AUTOSAR XML (schema 314)
package /ComponentType
  internal behavior Sa_CDDInterface_InternalBehavior: component=Sa_CDDInterface
    5 x timing event:
      CDDInterface_Init1_InitEvent: start-on-event=CDDInterface_Init1, period=0
      CDDInterface_Init2_InitEvent: start-on-event=CDDInterface_Init2, period=0
      TMT_CDDInterface_Per1: start-on-event=CDDInterface_Per1, period=0.002
      TMT_CDDInterface_Per2: start-on-event=CDDInterface_Per2, period=0.002
      TMT_CDDInterface_Per4: start-on-event=CDDInterface_Per4, period=0.01
    port-api-options:
      enable-take-address=false, indirect-api=false, port=ADCMtrCurr1
      enable-take-address=false, indirect-api=false, port=ADCMtrCurr2
      enable-take-address=false, indirect-api=false, port=CDDPorts
      enable-take-address=false, indirect-api=false, port=CommOffset
      enable-take-address=false, indirect-api=false, port=CorrectedElecMtrPos
      enable-take-address=false, indirect-api=false, port=CorrMtrCurrPosition
      enable-take-address=false, indirect-api=false, port=CorrMtrPosElec
      enable-take-address=false, indirect-api=false, port=CumMechMtrPos
      enable-take-address=false, indirect-api=false, port=DampingSrlComSvcDft
      enable-take-address=false, indirect-api=false, port=DftAsstTbl
      enable-take-address=false, indirect-api=false, port=Die1RxError
      enable-take-address=false, indirect-api=false, port=Die1RxMtrPos
      enable-take-address=false, indirect-api=false, port=Die1RxRevCtr
      enable-take-address=false, indirect-api=false, port=Die1UnderVoltgFltAccum
      enable-take-address=false, indirect-api=false, port=Die2RxError
      enable-take-address=false, indirect-api=false, port=Die2RxMtrPos
      enable-take-address=false, indirect-api=false, port=Die2RxRevCtr
      enable-take-address=false, indirect-api=false, port=DrivingDynSrlComSvcDft
      enable-take-address=false, indirect-api=false, port=DwnldAsstGain
      enable-take-address=false, indirect-api=false, port=EnergyModeState
      enable-take-address=false, indirect-api=false, port=EngONSrlComSvcDft
      enable-take-address=false, indirect-api=false, port=EOTImpactSrlComSvcDft
      enable-take-address=false, indirect-api=false, port=EOTThermalSrlComSvcDft
      enable-take-address=false, indirect-api=false, port=ExpectedOnTimeA
      enable-take-address=false, indirect-api=false, port=ExpectedOnTimeB
      enable-take-address=false, indirect-api=false, port=ExpectedOnTimeC
      enable-take-address=false, indirect-api=false, port=FreqDepDmpSrlComSvcDft
      enable-take-address=false, indirect-api=false, port=FricLrnSrlComSvcDft
      enable-take-address=false, indirect-api=false, port=HysAddSrlComSvcDft
      enable-take-address=false, indirect-api=false, port=HystCompSrlComSvcDft
      enable-take-address=false, indirect-api=false, port=IgnCnt
      enable-take-address=false, indirect-api=false, port=KinIntDiagSrlComSvcDft
      enable-take-address=false, indirect-api=false, port=LimitSrlComSvcDft
      enable-take-address=false, indirect-api=false, port=LRPRPhaseadvanceCaptured
      enable-take-address=false, indirect-api=false, port=MeasuredOnTimeA
      enable-take-address=false, indirect-api=false, port=MeasuredOnTimeB
      enable-take-address=false, indirect-api=false, port=MeasuredOnTimeC
      enable-take-address=false, indirect-api=false, port=MEC
      enable-take-address=false, indirect-api=false, port=MechMtrPos1
      enable-take-address=false, indirect-api=false, port=MechMtrPos1TimeStamp
      enable-take-address=false, indirect-api=false, port=MechMtrPos2TimeStamp
      enable-take-address=false, indirect-api=false, port=MfgDiagInhibit
      enable-take-address=false, indirect-api=false, port=ModIdxFinal
      enable-take-address=false, indirect-api=false, port=ModIdxSrlComSvcDft
      enable-take-address=false, indirect-api=false, port=MRFMtrVel
      enable-take-address=false, indirect-api=false, port=MtrCurr1TempOffset
      enable-take-address=false, indirect-api=false, port=MtrCurr2TempOffset
      enable-take-address=false, indirect-api=false, port=MtrCurrDax
      enable-take-address=false, indirect-api=false, port=MtrCurrK1
      enable-take-address=false, indirect-api=false, port=MtrCurrK2
      enable-take-address=false, indirect-api=false, port=MtrCurrQax
      enable-take-address=false, indirect-api=false, port=MtrCurrQaxFinalRef
      enable-take-address=false, indirect-api=false, port=MtrElecMechPolarity
      enable-take-address=false, indirect-api=false, port=MtrParmNrmLrnSrlComSvcDft
      enable-take-address=false, indirect-api=false, port=MtrPosPolarity
      enable-take-address=false, indirect-api=false, port=MtrTrqCmdSign
      enable-take-address=false, indirect-api=false, port=MtrVelNrmLrnSrlComSvcDft
      enable-take-address=false, indirect-api=false, port=MtrVoltDax
      enable-take-address=false, indirect-api=false, port=MtrVoltQax
      enable-take-address=false, indirect-api=false, port=MultIgnSrlComSvcDft
      enable-take-address=false, indirect-api=false, port=ParkAstSrlComSvcDft
      enable-take-address=false, indirect-api=false, port=PullCompSrlComSvcDft
      enable-take-address=false, indirect-api=false, port=ReturnSrlComSvcDft
      enable-take-address=false, indirect-api=false, port=RxMsgsSrlComSvcDft
      enable-take-address=false, indirect-api=false, port=RxMtrPosParityAccum
      enable-take-address=false, indirect-api=false, port=SrlComSvcDft
      enable-take-address=false, indirect-api=false, port=SysCCorrMtrPosElec
      enable-take-address=false, indirect-api=false, port=SysCVSwitchADC
      enable-take-address=false, indirect-api=false, port=SystemState
      enable-take-address=false, indirect-api=false, port=ThermalDCSrlComSvcDft
      enable-take-address=false, indirect-api=false, port=TrqRmpSrlComSvcDft
      enable-take-address=false, indirect-api=false, port=UncorrMechMtrPos1
      enable-take-address=false, indirect-api=false, port=Vecu
      enable-take-address=false, indirect-api=false, port=WhlImbRejSrlComSvcDft
    5 x runnable:
      CDDInterface_Init1
        data read access READ_MtrElecMechPolarity_Cnt_s08: data-element=MtrElecMechPolarity.Cnt_s08
        data read access READ_MtrPosPolarity_Cnt_s08: data-element=MtrPosPolarity.Cnt_s08
        data write access WRITE_IgnCnt_Cnt_u16: data-element=IgnCnt.Cnt_u16
        data write access WRITE_MEC_Cnt_enum: data-element=MEC.Cnt_enum
        sync call SC_CDDPorts_ApplyMtrElecMechPol: operation=CDDPorts.ApplyMtrElecMechPol, timeout=0
      CDDInterface_Init2
      CDDInterface_Per1
        35 x data write access:
          WRITE_ADCMtrCurr1_Volts_f32: data-element=ADCMtrCurr1.Volts_f32
          WRITE_ADCMtrCurr2_Volts_f32: data-element=ADCMtrCurr2.Volts_f32
          WRITE_CorrectedElecMtrPos_Rev_u0p16: data-element=CorrectedElecMtrPos.Rev_u0p16
          WRITE_CorrMtrCurrPosition_Rev_f32: data-element=CorrMtrCurrPosition.Rev_f32
          WRITE_CorrMtrPosElec_Rev_f32: data-element=CorrMtrPosElec.Rev_f32
          WRITE_CumMechMtrPos_Rev_f32: data-element=CumMechMtrPos.Rev_f32
          WRITE_Die1RxError_Cnt_u16: data-element=Die1RxError.Cnt_u16
          WRITE_Die1RxMtrPos_Cnt_u16: data-element=Die1RxMtrPos.Cnt_u16
          WRITE_Die1RxRevCtr_Cnt_u16: data-element=Die1RxRevCtr.Cnt_u16
          WRITE_Die1UnderVoltgFltAccum_Cnt_u16: data-element=Die1UnderVoltgFltAccum.Cnt_u16
          WRITE_Die2RxError_Cnt_u16: data-element=Die2RxError.Cnt_u16
          WRITE_Die2RxMtrPos_Cnt_u16: data-element=Die2RxMtrPos.Cnt_u16
          WRITE_Die2RxRevCtr_Cnt_u16: data-element=Die2RxRevCtr.Cnt_u16
          WRITE_ExpectedOnTimeA_Cnt_u32: data-element=ExpectedOnTimeA.Cnt_u32
          WRITE_ExpectedOnTimeB_Cnt_u32: data-element=ExpectedOnTimeB.Cnt_u32
          WRITE_ExpectedOnTimeC_Cnt_u32: data-element=ExpectedOnTimeC.Cnt_u32
          WRITE_LRPRPhaseadvanceCaptured_Cnt_s16: data-element=LRPRPhaseadvanceCaptured.Cnt_s16
          WRITE_MeasuredOnTimeA_Cnt_u32: data-element=MeasuredOnTimeA.Cnt_u32
          WRITE_MeasuredOnTimeB_Cnt_u32: data-element=MeasuredOnTimeB.Cnt_u32
          WRITE_MeasuredOnTimeC_Cnt_u32: data-element=MeasuredOnTimeC.Cnt_u32
          WRITE_MechMtrPos1_Rev_f32: data-element=MechMtrPos1.Rev_f32
          WRITE_MechMtrPos1TimeStamp_USec_u32: data-element=MechMtrPos1TimeStamp.USec_u32
          WRITE_MechMtrPos2TimeStamp_USec_u32: data-element=MechMtrPos2TimeStamp.USec_u32
          WRITE_ModIdxFinal_Uls_f32: data-element=ModIdxFinal.Uls_f32
          WRITE_MtrCurrDax_Amp_f32: data-element=MtrCurrDax.Amp_f32
          WRITE_MtrCurrK1_Amp_f32: data-element=MtrCurrK1.Amp_f32
          WRITE_MtrCurrK2_Amp_f32: data-element=MtrCurrK2.Amp_f32
          WRITE_MtrCurrQax_Amp_f32: data-element=MtrCurrQax.Amp_f32
          WRITE_MtrCurrQaxFinalRef_Amp_f32: data-element=MtrCurrQaxFinalRef.Amp_f32
          WRITE_MtrVoltDax_Volt_f32: data-element=MtrVoltDax.Volt_f32
          WRITE_MtrVoltQax_Volt_f32: data-element=MtrVoltQax.Volt_f32
          WRITE_RxMtrPosParityAccum_Cnt_u16: data-element=RxMtrPosParityAccum.Cnt_u16
          WRITE_SysCCorrMtrPosElec_Rev_f32: data-element=SysCCorrMtrPosElec.Rev_f32
          WRITE_SysCVSwitchADC_Cnt_u16: data-element=SysCVSwitchADC.Cnt_u16
          WRITE_UncorrMechMtrPos1_Rev_u0p16: data-element=UncorrMechMtrPos1.Rev_u0p16
        sync call SC_CDDPorts_ClearPhsReasSum: operation=CDDPorts.ClearPhsReasSum, timeout=0
      CDDInterface_Per2
        7 x data read access:
          READ_CommOffset_Cnt_u16: data-element=CommOffset.Cnt_u16
          READ_MRFMtrVel_MtrRadpS_f32: data-element=MRFMtrVel.MtrRadpS_f32
          READ_MtrCurr1TempOffset_Volt_f32: data-element=MtrCurr1TempOffset.Volt_f32
          READ_MtrCurr2TempOffset_Volt_f32: data-element=MtrCurr2TempOffset.Volt_f32
          READ_MtrPosPolarity_Cnt_s08: data-element=MtrPosPolarity.Cnt_s08
          READ_MtrTrqCmdSign_Cnt_s16: data-element=MtrTrqCmdSign.Cnt_s16
          READ_Vecu_Volt_f32: data-element=Vecu.Volt_f32
      CDDInterface_Per4
        data read access READ_MtrElecMechPolarity_Cnt_s08: data-element=MtrElecMechPolarity.Cnt_s08
        27 x data write access:
          WRITE_DampingSrlComSvcDft_Cnt_lgc: data-element=DampingSrlComSvcDft.Cnt_lgc
          WRITE_DftAsstTbl_Cnt_lgc: data-element=DftAsstTbl.Cnt_lgc
          WRITE_DrivingDynSrlComSvcDft_Cnt_lgc: data-element=DrivingDynSrlComSvcDft.Cnt_lgc
          WRITE_DwnldAsstGain_Uls_f32: data-element=DwnldAsstGain.Uls_f32
          WRITE_EnergyModeState_Cnt_enum: data-element=EnergyModeState.Cnt_enum
          WRITE_EngONSrlComSvcDft_Cnt_lgc: data-element=EngONSrlComSvcDft.Cnt_lgc
          WRITE_EOTImpactSrlComSvcDft_Cnt_lgc: data-element=EOTImpactSrlComSvcDft.Cnt_lgc
          WRITE_EOTThermalSrlComSvcDft_Cnt_lgc: data-element=EOTThermalSrlComSvcDft.Cnt_lgc
          WRITE_FreqDepDmpSrlComSvcDft_Cnt_lgc: data-element=FreqDepDmpSrlComSvcDft.Cnt_lgc
          WRITE_FricLrnSrlComSvcDft_Cnt_lgc: data-element=FricLrnSrlComSvcDft.Cnt_lgc
          WRITE_HysAddSrlComSvcDft_Cnt_lgc: data-element=HysAddSrlComSvcDft.Cnt_lgc
          WRITE_HystCompSrlComSvcDft_Cnt_lgc: data-element=HystCompSrlComSvcDft.Cnt_lgc
          WRITE_KinIntDiagSrlComSvcDft_Cnt_lgc: data-element=KinIntDiagSrlComSvcDft.Cnt_lgc
          WRITE_LimitSrlComSvcDft_Cnt_lgc: data-element=LimitSrlComSvcDft.Cnt_lgc
          WRITE_MfgDiagInhibit_Cnt_lgc: data-element=MfgDiagInhibit.Cnt_lgc
          WRITE_ModIdxSrlComSvcDft_Cnt_lgc: data-element=ModIdxSrlComSvcDft.Cnt_lgc
          WRITE_MtrParmNrmLrnSrlComSvcDft_Cnt_lgc: data-element=MtrParmNrmLrnSrlComSvcDft.Cnt_lgc
          WRITE_MtrVelNrmLrnSrlComSvcDft_Cnt_lgc: data-element=MtrVelNrmLrnSrlComSvcDft.Cnt_lgc
          WRITE_MultIgnSrlComSvcDft_Cnt_lgc: data-element=MultIgnSrlComSvcDft.Cnt_lgc
          WRITE_ParkAstSrlComSvcDft_Cnt_lgc: data-element=ParkAstSrlComSvcDft.Cnt_lgc
          WRITE_PullCompSrlComSvcDft_Cnt_lgc: data-element=PullCompSrlComSvcDft.Cnt_lgc
          WRITE_ReturnSrlComSvcDft_Cnt_lgc: data-element=ReturnSrlComSvcDft.Cnt_lgc
          WRITE_RxMsgsSrlComSvcDft_Cnt_lgc: data-element=RxMsgsSrlComSvcDft.Cnt_lgc
          WRITE_SrlComSvcDft_Cnt_b32: data-element=SrlComSvcDft.Cnt_b32
          WRITE_ThermalDCSrlComSvcDft_Cnt_lgc: data-element=ThermalDCSrlComSvcDft.Cnt_lgc
          WRITE_TrqRmpSrlComSvcDft_Cnt_lgc: data-element=TrqRmpSrlComSvcDft.Cnt_lgc
          WRITE_WhlImbRejSrlComSvcDft_Cnt_lgc: data-element=WhlImbRejSrlComSvcDft.Cnt_lgc
        sync call SC_CDDPorts_ApplyMtrElecMechPol: operation=CDDPorts.ApplyMtrElecMechPol, timeout=0
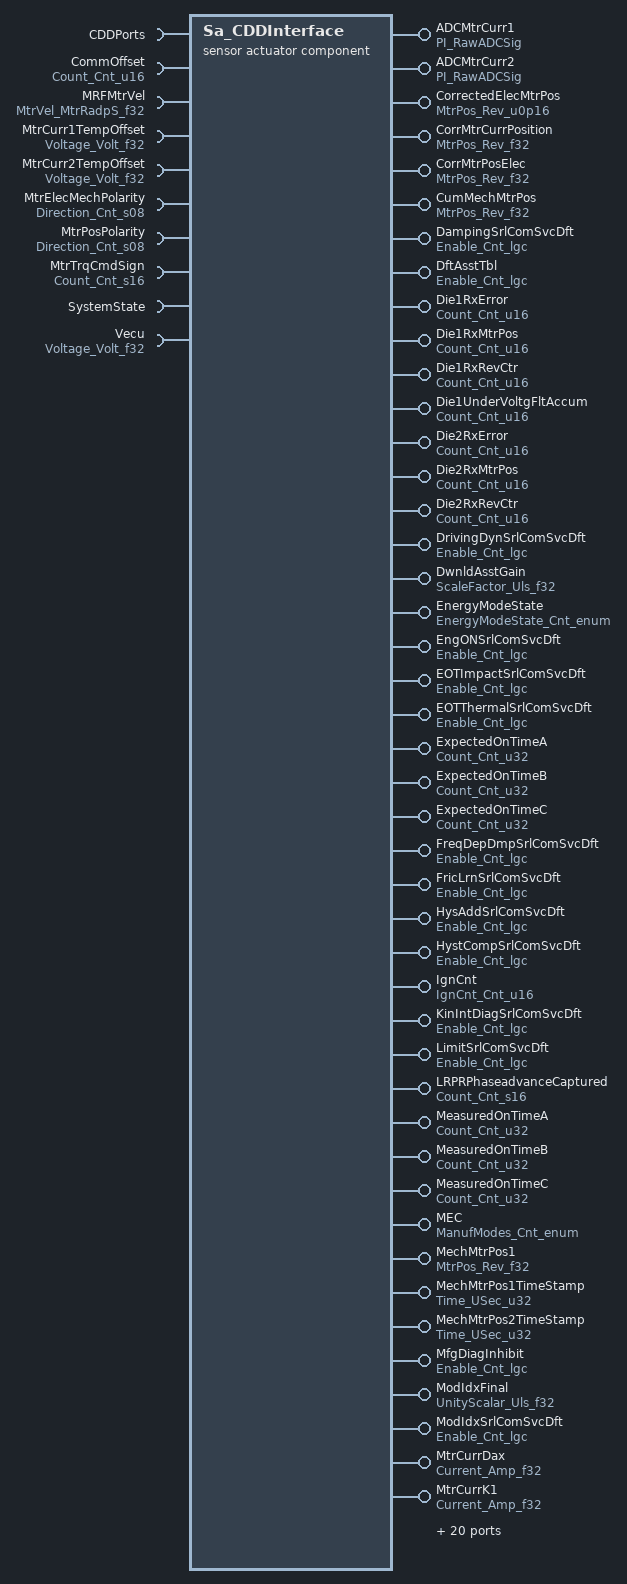
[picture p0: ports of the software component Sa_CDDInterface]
  sensor actuator software component type Sa_CDDInterface
    64 x provide port:
      ADCMtrCurr1: unqueued-sender-com-spec{data-element=Volts_f32, can-invalidate=false, init-value=D_ZERO_ULS_F32}, provided-interface=PI_RawADCSig
      ADCMtrCurr2: unqueued-sender-com-spec{data-element=Volts_f32, can-invalidate=false, init-value=D_ZERO_ULS_F32}, provided-interface=PI_RawADCSig
      CorrectedElecMtrPos: unqueued-sender-com-spec{data-element=Rev_u0p16, can-invalidate=false, init-value=D_ZERO_CNT_U16}, provided-interface=MtrPos_Rev_u0p16
      CorrMtrCurrPosition: unqueued-sender-com-spec{data-element=Rev_f32, can-invalidate=false, init-value=D_ZERO_ULS_F32}, provided-interface=MtrPos_Rev_f32
      CorrMtrPosElec: unqueued-sender-com-spec{data-element=Rev_f32, can-invalidate=false, init-value=D_ZERO_ULS_F32}, provided-interface=MtrPos_Rev_f32
      CumMechMtrPos: unqueued-sender-com-spec{data-element=Rev_f32, can-invalidate=false, init-value=D_ZERO_ULS_F32}, provided-interface=MtrPos_Rev_f32
      DampingSrlComSvcDft: unqueued-sender-com-spec{data-element=Cnt_lgc, can-invalidate=false, init-value=D_FALSE_CNT_LGC}, provided-interface=Enable_Cnt_lgc
      DftAsstTbl: unqueued-sender-com-spec{data-element=Cnt_lgc, can-invalidate=false, init-value=D_FALSE_CNT_LGC}, provided-interface=Enable_Cnt_lgc
      Die1RxError: unqueued-sender-com-spec{data-element=Cnt_u16, can-invalidate=false, init-value=D_ZERO_CNT_U16}, provided-interface=Count_Cnt_u16
      Die1RxMtrPos: unqueued-sender-com-spec{data-element=Cnt_u16, can-invalidate=false, init-value=D_ZERO_CNT_U16}, provided-interface=Count_Cnt_u16
      Die1RxRevCtr: unqueued-sender-com-spec{data-element=Cnt_u16, can-invalidate=false, init-value=D_ZERO_CNT_U16}, provided-interface=Count_Cnt_u16
      Die1UnderVoltgFltAccum: unqueued-sender-com-spec{data-element=Cnt_u16, can-invalidate=false, init-value=D_ZERO_CNT_U16}, provided-interface=Count_Cnt_u16
      Die2RxError: unqueued-sender-com-spec{data-element=Cnt_u16, can-invalidate=false, init-value=D_ZERO_CNT_U16}, provided-interface=Count_Cnt_u16
      Die2RxMtrPos: unqueued-sender-com-spec{data-element=Cnt_u16, can-invalidate=false, init-value=D_ZERO_CNT_U16}, provided-interface=Count_Cnt_u16
      Die2RxRevCtr: unqueued-sender-com-spec{data-element=Cnt_u16, can-invalidate=false, init-value=D_ZERO_CNT_U16}, provided-interface=Count_Cnt_u16
      DrivingDynSrlComSvcDft: unqueued-sender-com-spec{data-element=Cnt_lgc, can-invalidate=false, init-value=D_FALSE_CNT_LGC}, provided-interface=Enable_Cnt_lgc
      DwnldAsstGain: unqueued-sender-com-spec{data-element=Uls_f32, can-invalidate=false, init-value=D_ZERO_ULS_F32}, provided-interface=ScaleFactor_Uls_f32
      EnergyModeState: unqueued-sender-com-spec{data-element=Cnt_enum, can-invalidate=false, init-value=D_NORMALINIT_CNT_U16}, provided-interface=EnergyModeState_Cnt_enum
      EngONSrlComSvcDft: unqueued-sender-com-spec{data-element=Cnt_lgc, can-invalidate=false, init-value=D_FALSE_CNT_LGC}, provided-interface=Enable_Cnt_lgc
      EOTImpactSrlComSvcDft: unqueued-sender-com-spec{data-element=Cnt_lgc, can-invalidate=false, init-value=D_FALSE_CNT_LGC}, provided-interface=Enable_Cnt_lgc
      EOTThermalSrlComSvcDft: unqueued-sender-com-spec{data-element=Cnt_lgc, can-invalidate=false, init-value=D_FALSE_CNT_LGC}, provided-interface=Enable_Cnt_lgc
      ExpectedOnTimeA: unqueued-sender-com-spec{data-element=Cnt_u32, can-invalidate=false, init-value=D_ZERO_CNT_U32}, provided-interface=Count_Cnt_u32
      ExpectedOnTimeB: unqueued-sender-com-spec{data-element=Cnt_u32, can-invalidate=false, init-value=D_ZERO_CNT_U32}, provided-interface=Count_Cnt_u32
      ExpectedOnTimeC: unqueued-sender-com-spec{data-element=Cnt_u32, can-invalidate=false, init-value=D_ZERO_CNT_U32}, provided-interface=Count_Cnt_u32
      FreqDepDmpSrlComSvcDft: unqueued-sender-com-spec{data-element=Cnt_lgc, can-invalidate=false, init-value=D_FALSE_CNT_LGC}, provided-interface=Enable_Cnt_lgc
      FricLrnSrlComSvcDft: unqueued-sender-com-spec{data-element=Cnt_lgc, can-invalidate=false, init-value=D_FALSE_CNT_LGC}, provided-interface=Enable_Cnt_lgc
      HysAddSrlComSvcDft: unqueued-sender-com-spec{data-element=Cnt_lgc, can-invalidate=false, init-value=D_FALSE_CNT_LGC}, provided-interface=Enable_Cnt_lgc
      HystCompSrlComSvcDft: unqueued-sender-com-spec{data-element=Cnt_lgc, can-invalidate=false, init-value=D_FALSE_CNT_LGC}, provided-interface=Enable_Cnt_lgc
      IgnCnt: unqueued-sender-com-spec{data-element=Cnt_u16, can-invalidate=false, init-value=D_ZERO_CNT_U16}, provided-interface=IgnCnt_Cnt_u16
      KinIntDiagSrlComSvcDft: unqueued-sender-com-spec{data-element=Cnt_lgc, can-invalidate=false, init-value=D_FALSE_CNT_LGC}, provided-interface=Enable_Cnt_lgc
      LimitSrlComSvcDft: unqueued-sender-com-spec{data-element=Cnt_lgc, can-invalidate=false, init-value=D_FALSE_CNT_LGC}, provided-interface=Enable_Cnt_lgc
      LRPRPhaseadvanceCaptured: unqueued-sender-com-spec{data-element=Cnt_s16, can-invalidate=false, init-value=D_ZERO_CNT_S16}, provided-interface=Count_Cnt_s16
      MeasuredOnTimeA: unqueued-sender-com-spec{data-element=Cnt_u32, can-invalidate=false, init-value=D_ZERO_CNT_U32}, provided-interface=Count_Cnt_u32
      MeasuredOnTimeB: unqueued-sender-com-spec{data-element=Cnt_u32, can-invalidate=false, init-value=D_ZERO_CNT_U32}, provided-interface=Count_Cnt_u32
      MeasuredOnTimeC: unqueued-sender-com-spec{data-element=Cnt_u32, can-invalidate=false, init-value=D_ZERO_CNT_U32}, provided-interface=Count_Cnt_u32
      MEC: unqueued-sender-com-spec{data-element=Cnt_enum, can-invalidate=false, init-value=D_MANUFMODEINIT_CNT_ENUM}, provided-interface=ManufModes_Cnt_enum
      MechMtrPos1: unqueued-sender-com-spec{data-element=Rev_f32, can-invalidate=false, init-value=D_ZERO_ULS_F32}, provided-interface=MtrPos_Rev_f32
      MechMtrPos1TimeStamp: unqueued-sender-com-spec{data-element=USec_u32, can-invalidate=false, init-value=D_ZERO_CNT_U32}, provided-interface=Time_USec_u32
      MechMtrPos2TimeStamp: unqueued-sender-com-spec{data-element=USec_u32, can-invalidate=false, init-value=D_ZERO_CNT_U32}, provided-interface=Time_USec_u32
      MfgDiagInhibit: unqueued-sender-com-spec{data-element=Cnt_lgc, can-invalidate=false, init-value=D_FALSE_CNT_LGC}, provided-interface=Enable_Cnt_lgc
      ModIdxFinal: unqueued-sender-com-spec{data-element=Uls_f32, can-invalidate=false, init-value=D_ZERO_ULS_F32}, provided-interface=UnityScalar_Uls_f32
      ModIdxSrlComSvcDft: unqueued-sender-com-spec{data-element=Cnt_lgc, can-invalidate=false, init-value=D_FALSE_CNT_LGC}, provided-interface=Enable_Cnt_lgc
      MtrCurrDax: unqueued-sender-com-spec{data-element=Amp_f32, can-invalidate=false, init-value=D_ZERO_ULS_F32}, provided-interface=Current_Amp_f32
      MtrCurrK1: unqueued-sender-com-spec{data-element=Amp_f32, can-invalidate=false, init-value=D_ZERO_ULS_F32}, provided-interface=Current_Amp_f32
      MtrCurrK2: unqueued-sender-com-spec{data-element=Amp_f32, can-invalidate=false, init-value=D_ZERO_ULS_F32}, provided-interface=Current_Amp_f32
      MtrCurrQax: unqueued-sender-com-spec{data-element=Amp_f32, can-invalidate=false, init-value=D_ZERO_ULS_F32}, provided-interface=Current_Amp_f32
      MtrCurrQaxFinalRef: unqueued-sender-com-spec{data-element=Amp_f32, can-invalidate=false, init-value=D_ZERO_ULS_F32}, provided-interface=Current_Amp_f32
      MtrParmNrmLrnSrlComSvcDft: unqueued-sender-com-spec{data-element=Cnt_lgc, can-invalidate=false, init-value=D_FALSE_CNT_LGC}, provided-interface=Enable_Cnt_lgc
      MtrVelNrmLrnSrlComSvcDft: unqueued-sender-com-spec{data-element=Cnt_lgc, can-invalidate=false, init-value=D_FALSE_CNT_LGC}, provided-interface=Enable_Cnt_lgc
      MtrVoltDax: unqueued-sender-com-spec{data-element=Volt_f32, can-invalidate=false, init-value=D_ZERO_ULS_F32}, provided-interface=Voltage_Volt_f32
      MtrVoltQax: unqueued-sender-com-spec{data-element=Volt_f32, can-invalidate=false, init-value=D_ZERO_ULS_F32}, provided-interface=Voltage_Volt_f32
      MultIgnSrlComSvcDft: unqueued-sender-com-spec{data-element=Cnt_lgc, can-invalidate=false, init-value=D_FALSE_CNT_LGC}, provided-interface=Enable_Cnt_lgc
      ParkAstSrlComSvcDft: unqueued-sender-com-spec{data-element=Cnt_lgc, can-invalidate=false, init-value=D_FALSE_CNT_LGC}, provided-interface=Enable_Cnt_lgc
      PullCompSrlComSvcDft: unqueued-sender-com-spec{data-element=Cnt_lgc, can-invalidate=false, init-value=D_FALSE_CNT_LGC}, provided-interface=Enable_Cnt_lgc
      ReturnSrlComSvcDft: unqueued-sender-com-spec{data-element=Cnt_lgc, can-invalidate=false, init-value=D_FALSE_CNT_LGC}, provided-interface=Enable_Cnt_lgc
      RxMsgsSrlComSvcDft: unqueued-sender-com-spec{data-element=Cnt_lgc, can-invalidate=false, init-value=D_FALSE_CNT_LGC}, provided-interface=Enable_Cnt_lgc
      RxMtrPosParityAccum: unqueued-sender-com-spec{data-element=Cnt_u16, can-invalidate=false, init-value=D_ZERO_CNT_U16}, provided-interface=Count_Cnt_u16
      SrlComSvcDft: unqueued-sender-com-spec{data-element=Cnt_b32, can-invalidate=false, init-value=D_ZERO_CNT_U32}, provided-interface=SrlComSvcDft
      SysCCorrMtrPosElec: unqueued-sender-com-spec{data-element=Rev_f32, can-invalidate=false, init-value=D_ZERO_ULS_F32}, provided-interface=MtrPos_Rev_f32
      SysCVSwitchADC: unqueued-sender-com-spec{data-element=Cnt_u16, can-invalidate=false, init-value=D_ZERO_CNT_U16}, provided-interface=Count_Cnt_u16
      ThermalDCSrlComSvcDft: unqueued-sender-com-spec{data-element=Cnt_lgc, can-invalidate=false, init-value=D_FALSE_CNT_LGC}, provided-interface=Enable_Cnt_lgc
      TrqRmpSrlComSvcDft: unqueued-sender-com-spec{data-element=Cnt_lgc, can-invalidate=false, init-value=D_FALSE_CNT_LGC}, provided-interface=Enable_Cnt_lgc
      UncorrMechMtrPos1: unqueued-sender-com-spec{data-element=Rev_u0p16, can-invalidate=false, init-value=D_ZERO_CNT_U16}, provided-interface=MtrPos_Rev_u0p16
      WhlImbRejSrlComSvcDft: unqueued-sender-com-spec{data-element=Cnt_lgc, can-invalidate=false, init-value=D_FALSE_CNT_LGC}, provided-interface=Enable_Cnt_lgc
    10 x require port:
      CDDPorts: required-com-specs=[ApplyMtrElecMechPol, ClearPhsReasSum], required-interface=CDDPorts
      CommOffset: unqueued-receiver-com-spec{data-element=Cnt_u16, init-value=D_ZERO_CNT_U16}, required-interface=Count_Cnt_u16
      MRFMtrVel: unqueued-receiver-com-spec{data-element=MtrRadpS_f32, init-value=D_ZERO_ULS_F32}, required-interface=MtrVel_MtrRadpS_f32
      MtrCurr1TempOffset: unqueued-receiver-com-spec{data-element=Volt_f32, init-value=D_ZERO_ULS_F32}, required-interface=Voltage_Volt_f32
      MtrCurr2TempOffset: unqueued-receiver-com-spec{data-element=Volt_f32, init-value=D_ZERO_ULS_F32}, required-interface=Voltage_Volt_f32
      MtrElecMechPolarity: unqueued-receiver-com-spec{data-element=Cnt_s08, init-value=D_ZERO_CNT_S8}, required-interface=Direction_Cnt_s08
      MtrPosPolarity: unqueued-receiver-com-spec{data-element=Cnt_s08, init-value=D_ZERO_CNT_S8}, required-interface=Direction_Cnt_s08
      MtrTrqCmdSign: unqueued-receiver-com-spec{data-element=Cnt_s16, init-value=D_ZERO_CNT_S16}, required-interface=Count_Cnt_s16
      SystemState: required-interface=SystemState
      Vecu: unqueued-receiver-com-spec{data-element=Volt_f32, init-value=D_VECUMIN_VOLTS_F32}, required-interface=Voltage_Volt_f32
  swc implementation Sa_CDDInterface_Implementation: behavior=Sa_CDDInterface_InternalBehavior
    code-descriptors:
      code Code: type=SRC
